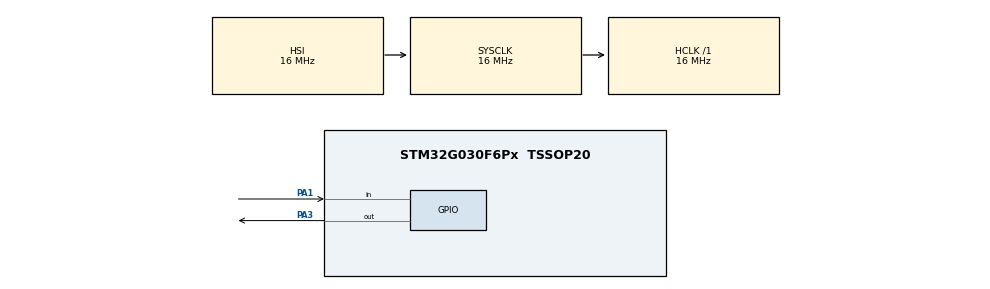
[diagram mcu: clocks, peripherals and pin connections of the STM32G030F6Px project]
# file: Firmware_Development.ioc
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FREERTOS.Tasks01=defaultTask,0,128,StartDefaultTask,Default,NULL,Dynamic,NULL,NULL
Mcu.Family=STM32G0
Mcu.Name=STM32G030F6Px
Mcu.Package=TSSOP20
PA1.GPIO_PuPd=GPIO_PULLUP
PA1.Signal=GPIO_Input
PA14-BOOT0__PA15.StandardMode=true
PA3.Signal=GPIO_Output
PB0__PB1__PB2__PA8.StandardMode=true
PB3__PB4__PB5__PB6.StandardMode=true
PB7__PB8.StandardMode=true
PC14-OSC32_IN\ (PC14)__PB9.StandardMode=true
ProjectManager.HeapSize=0x200
ProjectManager.StackSize=0x400
ProjectManager.TargetToolchain=STM32CubeIDE
RCC.AHBFreq_Value=16000000
RCC.CortexFreq_Value=16000000
RCC.EXTERNAL_CLOCK_VALUE=12288000
RCC.HCLKFreq_Value=16000000
RCC.HSE_VALUE=8000000
RCC.HSI_VALUE=16000000
RCC.LSE_VALUE=32768
RCC.SYSCLKFreq_VALUE=16000000
RCC.VCOOutputFreq_Value=128000000
VP_FREERTOS_VS_CMSIS_V1.Mode=CMSIS_V1
board=custom

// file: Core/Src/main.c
/* USER CODE BEGIN Header */
/**
  ******************************************************************************
  * @file           : main.c
  * @brief          : Main program body
  ******************************************************************************
  * @attention
  *
  * Copyright (c) 2024 STMicroelectronics.
  * All rights reserved.
  *
  * This software is licensed under terms that can be found in the LICENSE file
  * in the root directory of this software component.
  * If no LICENSE file comes with this software, it is provided AS-IS.
  *
  ******************************************************************************
  */
/* USER CODE END Header */
#include "main.h"
#include "cmsis_os.h"

osThreadId buttonTaskHandle;

void SystemClock_Config(void);
static void MX_GPIO_Init(void);
void ButtonStartTask(void const * argument);

/* USER CODE BEGIN PFP */

uint32_t last_toggle_time = 0;
uint32_t operation_start_time = 0;
const uint32_t toggle_interval = 500; // 500 ms interval
volatile uint8_t operation_started = 0;
volatile uint32_t button_press_time = 0;
const uint32_t long_press_duration = 5000; // 5 seconds
const uint32_t auto_shut_off_duration = 30 * 1000; // 30 seconds
volatile uint32_t current_time;

uint32_t port_A = GPIOA;
uint32_t motor_con_pin = GPIO_PIN_3;
uint32_t sw_pin = GPIO_PIN_1;

uint8_t long_press_detected = 0;
void motor_operation(void);
/* USER CODE END PFP */

int main(void)
{

  /* MCU Configuration--------------------------------------------------------*/

  /* Reset of all peripherals, Initializes the Flash interface and the Systick. */
  HAL_Init();

  /* Configure the system clock */
  SystemClock_Config();

  /* Initialize all configured peripherals */
  MX_GPIO_Init();
  /* USER CODE BEGIN 2 */
  /* creation of sensorTask */
//      sensorTaskHandle = osThreadNew(buttonTaskFunc, NULL, &buttonTask_attributes);
  /* USER CODE END 2 */

  /* Create the thread(s) */
  /* definition and creation of buttonTask */
  osThreadDef(buttonTask, ButtonStartTask, osPriorityNormal, 0, 128);
  buttonTaskHandle = osThreadCreate(osThread(buttonTask), NULL);

  /* Start scheduler */
  osKernelStart();

  /* We should never get here as control is now taken by the scheduler */
  /* Infinite loop */
  /* USER CODE BEGIN WHILE */
  while (1)
  {
//    motor_operation();
    /* USER CODE END WHILE */
	  motor_operation();
  }
}

void motor_operation(void)
{
    current_time = HAL_GetTick();

    if (operation_started) //operation starts when PA0 is pressed for short time less than 5sec
    {
        if ((current_time - operation_start_time)  >= auto_shut_off_duration) // autoshutdown operation after 30 seconds
        {
            operation_started = 0;
            HAL_GPIO_WritePin(GPIOA, motor_con_pin, GPIO_PIN_SET); // Turn off operation
        }
//        else if ((current_time - last_toggle_time) >= toggle_interval) // checking the interval and toggle accordingly
//        {
//            HAL_GPIO_TogglePin(port_A, motor_con_pin);
            HAL_GPIO_WritePin(GPIOA, motor_con_pin, GPIO_PIN_RESET); // Turn On operation
//            last_toggle_time = current_time;
//        }
    }

}

/* External interrupt callback */
void HAL_GPIO_EXTI_Callback(uint16_t GPIO_Pin) // set for short and long press (>=5sec)
{
    if (GPIO_Pin == sw_pin)
    {
    	if (!operation_started)
    	{
			operation_started = 1;
			operation_start_time = HAL_GetTick();
    	}
    }
}

void SystemClock_Config(void)
{
  RCC_OscInitTypeDef RCC_OscInitStruct = {0};
  RCC_ClkInitTypeDef RCC_ClkInitStruct = {0};

  /** Configure the main internal regulator output voltage
  */
  HAL_PWREx_ControlVoltageScaling(PWR_REGULATOR_VOLTAGE_SCALE1);

  /** Initializes the RCC Oscillators according to the specified parameters
  * in the RCC_OscInitTypeDef structure.
  */
  RCC_OscInitStruct.OscillatorType = RCC_OSCILLATORTYPE_HSI;
  RCC_OscInitStruct.HSIState = RCC_HSI_ON;
  RCC_OscInitStruct.HSIDiv = RCC_HSI_DIV1;
  RCC_OscInitStruct.HSICalibrationValue = RCC_HSICALIBRATION_DEFAULT;
  RCC_OscInitStruct.PLL.PLLState = RCC_PLL_NONE;
  if (HAL_RCC_OscConfig(&RCC_OscInitStruct) != HAL_OK)
  {
    Error_Handler();
  }

  /** Initializes the CPU, AHB and APB buses clocks
  */
  RCC_ClkInitStruct.ClockType = RCC_CLOCKTYPE_HCLK|RCC_CLOCKTYPE_SYSCLK
                              |RCC_CLOCKTYPE_PCLK1;
  RCC_ClkInitStruct.SYSCLKSource = RCC_SYSCLKSOURCE_HSI;
  RCC_ClkInitStruct.AHBCLKDivider = RCC_SYSCLK_DIV1;
  RCC_ClkInitStruct.APB1CLKDivider = RCC_HCLK_DIV1;

  if (HAL_RCC_ClockConfig(&RCC_ClkInitStruct, FLASH_LATENCY_0) != HAL_OK)
  {
    Error_Handler();
  }
}

static void MX_GPIO_Init(void)
{
  GPIO_InitTypeDef GPIO_InitStruct = {0};

  /* GPIO Ports Clock Enable */
  __HAL_RCC_GPIOA_CLK_ENABLE();

  /*Configure GPIO pin Output Level */
  HAL_GPIO_WritePin(GPIOA, GPIO_PIN_3, GPIO_PIN_RESET);

  /*Configure GPIO pin : PA1 */
  GPIO_InitStruct.Pin = GPIO_PIN_1;
  GPIO_InitStruct.Mode = GPIO_MODE_INPUT;
  GPIO_InitStruct.Pull = GPIO_PULLUP;
  HAL_GPIO_Init(GPIOA, &GPIO_InitStruct);

  /*Configure GPIO pin : PA3 */
  GPIO_InitStruct.Pin = GPIO_PIN_3;
  GPIO_InitStruct.Mode = GPIO_MODE_OUTPUT_PP;
  GPIO_InitStruct.Pull = GPIO_NOPULL;
  GPIO_InitStruct.Speed = GPIO_SPEED_FREQ_LOW;
  HAL_GPIO_Init(GPIOA, &GPIO_InitStruct);
	/* EXTI interrupt init */
	  HAL_NVIC_SetPriority(EXTI0_1_IRQn, 2, 0);
	  HAL_NVIC_EnableIRQ(EXTI0_1_IRQn);
}

void ButtonStartTask(void const * argument)
{
  /* USER CODE BEGIN 5 */
	uint8_t button_pressed;
  /* Infinite loop */
  for(;;)
  {

	  if(HAL_GPIO_ReadPin(GPIOA, sw_pin) == GPIO_PIN_RESET)
	  {

		if (button_pressed)
			{
				button_press_time = HAL_GetTick();
				button_pressed = 0;
			}
		else if ((HAL_GetTick() - button_press_time) >= long_press_duration)

			{
				//Reset
				operation_started = 0;
//				button_pressed = 1;
				HAL_GPIO_WritePin(port_A, motor_con_pin, GPIO_PIN_SET); //check PA3 is off
			}
	   }
	  else
		  button_pressed = 1;

    osDelay(1);
  }
  /* USER CODE END 5 */
}

void Error_Handler(void)
{
    __disable_irq();
    while (1)
    {
    }
}
